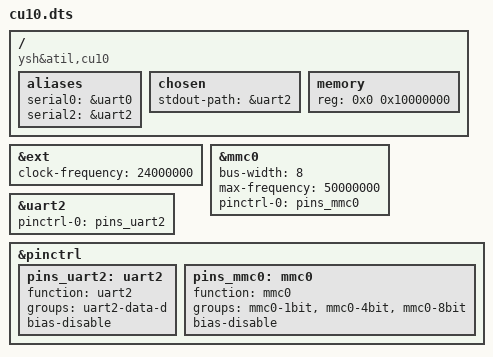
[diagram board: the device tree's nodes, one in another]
// SPDX-License-Identifier: GPL-2.0
/dts-v1/;

#include "x1000.dtsi"
#include <dt-bindings/gpio/gpio.h>

/ {
	compatible = "ysh&atil,cu10", "ingenic,x1000";

	aliases {
		serial0 = &uart0;
		serial2 = &uart2;
	};

	chosen {
		stdout-path = &uart2;
	};

	memory {
		device_type = "memory";
		reg = <0x0 0x10000000>;
	};
};

&ext {
	clock-frequency = <24000000>;
};

&mmc0 {
	status = "okay";

	bus-width = <8>;
	max-frequency = <50000000>;

	pinctrl-names = "default";
	pinctrl-0 = <&pins_mmc0>;
};

&uart2 {
	status = "okay";

	pinctrl-names = "default";
	pinctrl-0 = <&pins_uart2>;
};

&pinctrl {
	pins_uart2: uart2 {
		function = "uart2";
		groups = "uart2-data-d";
		bias-disable;
	};

	pins_mmc0: mmc0 {
		function = "mmc0";
		groups = "mmc0-1bit", "mmc0-4bit", "mmc0-8bit";
		bias-disable;
	};
};
